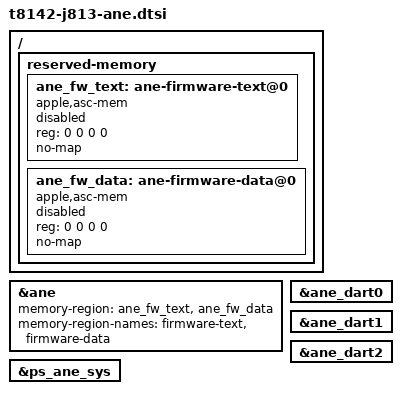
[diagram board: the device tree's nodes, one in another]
// SPDX-License-Identifier: GPL-2.0+ OR MIT
/*
 * The J813/J815 Neural Engine. iBoot preloads the personalized firmware (ADT
 * ane0 segment-ranges; the 27.0 stub's TEXT is 0xc0000 and DATA 0x2ac000
 * bytes). The boot loader fills the two reservations from that boot's ADT,
 * renames them to their physical addresses and enables them; until then the
 * ANE driver leaves the engine off.
 */

/ {
	reserved-memory {
		ane_fw_text: ane-firmware-text@0 {
			compatible = "apple,asc-mem";
			reg = <0 0 0 0>;
			no-map;
			status = "disabled";
		};

		ane_fw_data: ane-firmware-data@0 {
			compatible = "apple,asc-mem";
			reg = <0 0 0 0>;
			no-map;
			status = "disabled";
		};
	};
};

&ane {
	memory-region = <&ane_fw_text>, <&ane_fw_data>;
	memory-region-names = "firmware-text", "firmware-data";
	status = "okay";
};

&ane_dart0 {
	status = "okay";
};

&ane_dart1 {
	status = "okay";
};

&ane_dart2 {
	status = "okay";
};

&ps_ane_sys {
	status = "okay";
};
